AUTOSAR XML (schema 4-0-3)
standard types defined: Boolean, UInt32
package /AUTOSAR_Platform/DataConstrs
  range DC_Boolean: raw 0..1
package /PATAC/Facility/DataTypes/Implementation
  compu method COMPU_Boolean: 0=FALSE, 1=TRUE
  unit NoUnit: factor-si-to-unit=1, offset-si-to-unit=0
package /PATAC/MSM/ComponentTypes
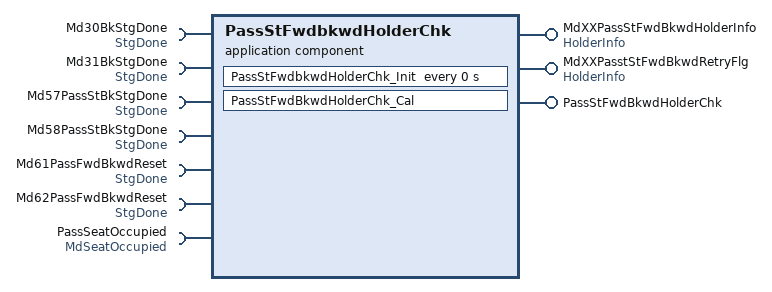
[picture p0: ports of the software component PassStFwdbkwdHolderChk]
  application sw component type PassStFwdbkwdHolderChk
    provide port MdXXPassStFwdBkwdHolderInfo: nonqueued-sender-com-spec{data-element=HolderInfo/Val, init-value=0}, provided-interface=HolderInfo
    provide port MdXXPasstStFwdBkwdRetryFlg: nonqueued-sender-com-spec{data-element=HolderInfo/Val, init-value=0}, provided-interface=HolderInfo
    provide port PassStFwdBkwdHolderChk: server-com-spec{operation=Cal, queue-length=1}, provided-interface=PassStFwdBkwdHolderChk
    7 x require port:
      Md30BkStgDone: nonqueued-receiver-com-spec{data-element=StgDone/Val, filter=data-filter-type=ALWAYS, init-value=0}, required-interface=StgDone
      Md31BkStgDone: nonqueued-receiver-com-spec{data-element=StgDone/Val, filter=data-filter-type=ALWAYS, init-value=0}, required-interface=StgDone
      Md57PassStBkStgDone: nonqueued-receiver-com-spec{data-element=StgDone/Val, filter=data-filter-type=ALWAYS, init-value=0}, required-interface=StgDone
      Md58PassStBkStgDone: nonqueued-receiver-com-spec{data-element=StgDone/Val, filter=data-filter-type=ALWAYS, init-value=0}, required-interface=StgDone
      Md61PassFwdBkwdReset: nonqueued-receiver-com-spec{data-element=StgDone/Val, filter=data-filter-type=ALWAYS, init-value=0}, required-interface=StgDone
      Md62PassFwdBkwdReset: nonqueued-receiver-com-spec{data-element=StgDone/Val, filter=data-filter-type=ALWAYS, init-value=0}, required-interface=StgDone
      PassSeatOccupied: nonqueued-receiver-com-spec{data-element=MdSeatOccupied/Val, filter=data-filter-type=ALWAYS, init-value=0}, required-interface=MdSeatOccupied
    behavior PassStFwdbkwdHolderChk_InternalBehavior
      operation invoked event OIT_PassStFwdBkwdHolderChk_Cal_PassStFwdBkwdHolderChk_Cal: start-on-event=PassStFwdBkwdHolderChk_Cal, operation=PassStFwdBkwdHolderChk.Cal
      timing event PassStFwdbkwdHolderChk_InitEvent: start-on-event=PassStFwdbkwdHolderChk_Init, period=0
      runnable PassStFwdBkwdHolderChk_Cal
        data-receive-point-by-arguments:
          7 x access:
            REC_Md30BkStgDone_Val: accessed-variable=Md30BkStgDone.Val
            REC_Md31BkStgDone_Val: accessed-variable=Md31BkStgDone.Val
            REC_Md57PassStBkStgDone_Val: accessed-variable=Md57PassStBkStgDone.Val
            REC_Md58PassStBkStgDone_Val: accessed-variable=Md58PassStBkStgDone.Val
            REC_Md61PassFwdBkwdReset_Val: accessed-variable=Md61PassFwdBkwdReset.Val
            REC_Md62PassFwdBkwdReset_Val: accessed-variable=Md62PassFwdBkwdReset.Val
            REC_PassSeatOccupied_Val: accessed-variable=PassSeatOccupied.Val
        data-send-points:
          access SEND_MdXXPassStFwdBkwdHolderInfo_Val: accessed-variable=MdXXPassStFwdBkwdHolderInfo.Val
          access SEND_MdXXPasstStFwdBkwdRetryFlg_Val: accessed-variable=MdXXPasstStFwdBkwdRetryFlg.Val
      runnable PassStFwdbkwdHolderChk_Init
  swc implementation PassStFwdbkwdHolderChk_Implementation: behavior=PassStFwdbkwdHolderChk_InternalBehavior
    code-descriptors:
      code Default: artifact-descriptors=autosar-engineering-object={short-label=Default, category=SWSRC}
package /PATAC/MSM/ModeAdjust/PortInterface
  client server interface PassStFwdBkwdHolderChk
    operation Cal
  sender receiver interface HolderInfo: invalidation-policy{data-element=HolderInfo/Val, handle-invalid=DONT-INVALIDATE}
    data Val: type=UInt32
  sender receiver interface MdSeatOccupied: invalidation-policy{data-element=MdSeatOccupied/Val, handle-invalid=DONT-INVALIDATE}
    data Val: type=Boolean
  sender receiver interface StgDone: invalidation-policy{data-element=StgDone/Val, handle-invalid=DONT-INVALIDATE}
    data Val: type=Boolean
